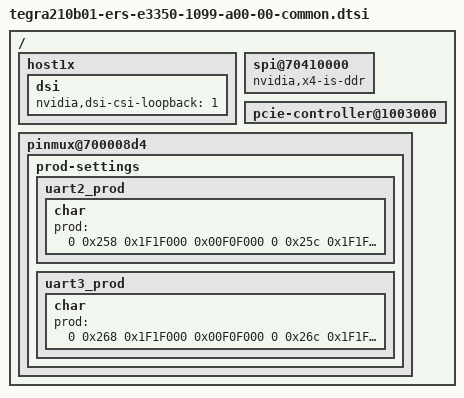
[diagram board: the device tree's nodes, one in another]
/*
 * Copyright (c) 2017, NVIDIA CORPORATION.  All rights reserved.
 *
 * This program is free software; you can redistribute it and/or modify
 * it under the terms of the GNU General Public License as published by
 * the Free Software Foundation; version 2 of the License.
 *
 * This program is distributed in the hope that it will be useful, but WITHOUT
 * ANY WARRANTY; without even the implied warranty of MERCHANTABILITY or
 * FITNESS FOR A PARTICULAR PURPOSE.  See the GNU General Public License for
 * more details.
 *
 * You should have received a copy of the GNU General Public License along
 * with this program; if not, write to the Free Software Foundation, Inc.,
 * 51 Franklin Street, Fifth Floor, Boston, MA  02110-1301, USA.
 *
 */

#include "tegra210b01-ers-e3350-1000-a00-00-common.dtsi"

/ {
	host1x {
		dsi {
			nvidia,dsi-csi-loopback = <1>;
		};
	};

        spi@70410000 {
                nvidia,x4-is-ddr;
                status = "okay";
        };

	pcie-controller@1003000 {
		/delete-property/ nvidia,wake-gpio;
	};

	pinmux@700008d4 {
		prod-settings {
			uart2_prod {
				status = "okay";
				char {
					prod = <0 0x258 0x1F1F000 0x00F0F000
						0 0x25c 0x1F1F000 0x00F0F000
						0 0x260 0x1F1F000 0x00F0F000
						0 0x264 0x1F1F000 0x00F0F000>;
				};
			};
			uart3_prod {
				status = "okay";
				char {
					prod = <0 0x268 0x1F1F000 0x00F0F000
						0 0x26c 0x1F1F000 0x00F0F000
						0 0x270 0x1F1F000 0x00F0F000
						0 0x274 0x1F1F000 0x00F0F000>;
				};
			};
		};
	};
};
